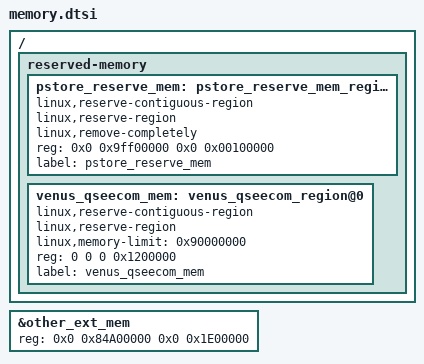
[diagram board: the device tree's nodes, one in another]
&other_ext_mem {
    reg = <0x0 0x84A00000 0x0 0x1E00000>;
};

/ {
	reserved-memory {
		pstore_reserve_mem: pstore_reserve_mem_region@0 {
			linux,reserve-contiguous-region;
			linux,reserve-region;
			linux,remove-completely;
			reg = <0x0 0x9ff00000 0x0 0x00100000>;
			label = "pstore_reserve_mem";
		};

		venus_qseecom_mem: venus_qseecom_region@0 {
			linux,reserve-contiguous-region;
			linux,reserve-region;
			linux,memory-limit = <0x90000000>;
			reg = <0 0 0 0x1200000>;
			label = "venus_qseecom_mem";
		};
	};
};
